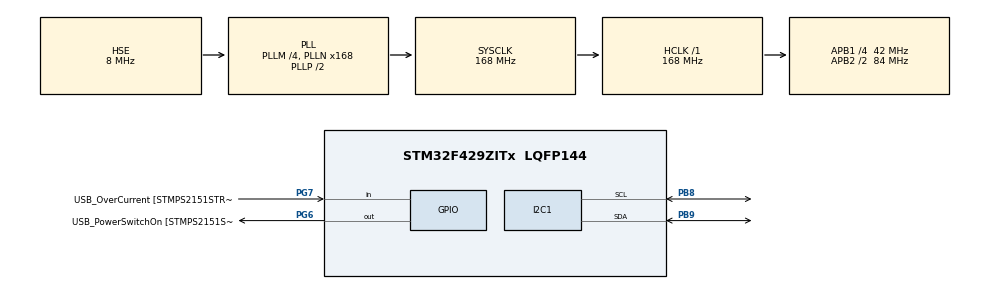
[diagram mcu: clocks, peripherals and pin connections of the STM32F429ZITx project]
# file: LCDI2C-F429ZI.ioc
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Mcu.Family=STM32F4
RCC.PLLSourceVirtual=RCC_PLLSOURCE_HSE
RCC.CortexFreq_Value=168000000
PG6.Signal=GPIO_Output
PG7.Signal=GPIO_Input
PA14.GPIO_Label=TCK
PG6.GPIO_Label=USB_PowerSwitchOn [STMPS2151STR_EN]
RCC.SYSCLKSourceVirtual=RCC_SYSCLKSOURCE_PLLCLK
PC14/OSC32_IN.Mode=LSE-External-Oscillator
RCC.APB1CLKDivider=RCC_HCLK_DIV4
RCC.SYSCLKSource=RCC_SYSCLKSOURCE_PLLCLK
ProjectManager.StackSize=0x400
PA13.Signal=SYS_JTMS-SWDIO
ProjectManager.TargetToolchain=STM32CubeIDE
PH0/OSC_IN.Mode=HSE-External-Clock-Source
RCC.HCLKFreq_Value=168000000
PB9.Mode=I2C
RCC.APB2TimFreq_Value=168000000
PH1/OSC_OUT.Signal=RCC_OSC_OUT
RCC.USBFreq_Value=48000000
RCC.AHBFreq_Value=168000000
RCC.HSE_VALUE=8000000
board=NUCLEO-F429ZI
RCC.VCOOutputFreq_Value=336000000
RCC.PLLMUL=RCC_PLL_MUL9
PH0/OSC_IN.Signal=RCC_OSC_IN
RCC.APB2Freq_Value=84000000
RCC.PRESCALERUSB=RCC_USBCLKSOURCE_PLL_DIV1_5
PA14.Mode=Serial_Wire
PG7.GPIO_Label=USB_OverCurrent [STMPS2151STR_FAULT]
PA13.Mode=Serial_Wire
PH1/OSC_OUT.Mode=HSE-External-Clock-Source
Mcu.Name=STM32F429ZITx
PA13.GPIO_Label=TMS
RCC.APB2TimCLKDivider=2
RCC.48MHZClocksFreq_Value=48000000
RCC.SYSCLKFreq_VALUE=168000000
Mcu.Package=LQFP144
PB9.Signal=I2C1_SDA
PC14/OSC32_IN.Signal=RCC_OSC32_IN
PC15/OSC32_OUT.Mode=LSE-External-Oscillator
PA14.Signal=SYS_JTCK-SWCLK
ProjectManager.HeapSize=0x200
RCC.HSI_VALUE=16000000
PH0/OSC_IN.GPIO_Label=MCO [STM32F103CBT6_PA8]
RCC.PLLQ=7
NVIC.PriorityGroup=NVIC_PRIORITYGROUP_4
RCC.APB2CLKDivider=RCC_HCLK_DIV2
RCC.PLLM=4
PB8.Mode=I2C
RCC.PLLN=168
RCC.APB1TimFreq_Value=84000000
PB8.Signal=I2C1_SCL
PC15/OSC32_OUT.Signal=RCC_OSC32_OUT
RCC.APB1Freq_Value=42000000

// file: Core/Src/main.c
/* USER CODE BEGIN Header */
/**
  ******************************************************************************
  * @file           : main.c
  * @brief          : Main program body
  ******************************************************************************
  * @attention
  *
  * <h2><center>&copy; Copyright (c) 2021 STMicroelectronics.
  * All rights reserved.</center></h2>
  *
  * This software component is licensed by ST under BSD 3-Clause license,
  * the "License"; You may not use this file except in compliance with the
  * License. You may obtain a copy of the License at:
  *                        opensource.org/licenses/BSD-3-Clause
  *
  ******************************************************************************
  */
/* USER CODE END Header */
#include "main.h"

/* USER CODE BEGIN Includes */
#include "LCDI2C.h"
/* USER CODE END Includes */

I2C_HandleTypeDef hi2c1;

void SystemClock_Config(void);
static void MX_GPIO_Init(void);
static void MX_I2C1_Init(void);

int main(void)
{

  /* MCU Configuration--------------------------------------------------------*/

  /* Reset of all peripherals, Initializes the Flash interface and the Systick. */
  HAL_Init();

  /* Configure the system clock */
  SystemClock_Config();

  /* Initialize all configured peripherals */
  MX_GPIO_Init();
  MX_I2C1_Init();
  /* USER CODE BEGIN 2 */
  LCD_initID(0x4E); //I2C Address
  LCD_Init();	//Initialization
  /* USER CODE END 2 */

  /* Infinite loop */
  while (1)
  {
	  LCD_setCursor(0,0);
	  LCD_sendSTR("Hello World");
  }
}

void SystemClock_Config(void)
{
  RCC_OscInitTypeDef RCC_OscInitStruct = {0};
  RCC_ClkInitTypeDef RCC_ClkInitStruct = {0};

  /** Configure the main internal regulator output voltage
  */
  __HAL_RCC_PWR_CLK_ENABLE();
  __HAL_PWR_VOLTAGESCALING_CONFIG(PWR_REGULATOR_VOLTAGE_SCALE1);
  /** Initializes the RCC Oscillators according to the specified parameters
  * in the RCC_OscInitTypeDef structure.
  */
  RCC_OscInitStruct.OscillatorType = RCC_OSCILLATORTYPE_HSE;
  RCC_OscInitStruct.HSEState = RCC_HSE_BYPASS;
  RCC_OscInitStruct.PLL.PLLState = RCC_PLL_ON;
  RCC_OscInitStruct.PLL.PLLSource = RCC_PLLSOURCE_HSE;
  RCC_OscInitStruct.PLL.PLLM = 4;
  RCC_OscInitStruct.PLL.PLLN = 168;
  RCC_OscInitStruct.PLL.PLLP = RCC_PLLP_DIV2;
  RCC_OscInitStruct.PLL.PLLQ = 7;
  if (HAL_RCC_OscConfig(&RCC_OscInitStruct) != HAL_OK)
  {
    Error_Handler();
  }
  /** Initializes the CPU, AHB and APB buses clocks
  */
  RCC_ClkInitStruct.ClockType = RCC_CLOCKTYPE_HCLK|RCC_CLOCKTYPE_SYSCLK
                              |RCC_CLOCKTYPE_PCLK1|RCC_CLOCKTYPE_PCLK2;
  RCC_ClkInitStruct.SYSCLKSource = RCC_SYSCLKSOURCE_PLLCLK;
  RCC_ClkInitStruct.AHBCLKDivider = RCC_SYSCLK_DIV1;
  RCC_ClkInitStruct.APB1CLKDivider = RCC_HCLK_DIV4;
  RCC_ClkInitStruct.APB2CLKDivider = RCC_HCLK_DIV2;

  if (HAL_RCC_ClockConfig(&RCC_ClkInitStruct, FLASH_LATENCY_5) != HAL_OK)
  {
    Error_Handler();
  }
}

static void MX_I2C1_Init(void)
{

  hi2c1.Instance = I2C1;
  hi2c1.Init.ClockSpeed = 100000;
  hi2c1.Init.DutyCycle = I2C_DUTYCYCLE_2;
  hi2c1.Init.OwnAddress1 = 0;
  hi2c1.Init.AddressingMode = I2C_ADDRESSINGMODE_7BIT;
  hi2c1.Init.DualAddressMode = I2C_DUALADDRESS_DISABLE;
  hi2c1.Init.OwnAddress2 = 0;
  hi2c1.Init.GeneralCallMode = I2C_GENERALCALL_DISABLE;
  hi2c1.Init.NoStretchMode = I2C_NOSTRETCH_DISABLE;
  if (HAL_I2C_Init(&hi2c1) != HAL_OK)
  {
    Error_Handler();
  }
  /** Configure Analogue filter
  */
  if (HAL_I2CEx_ConfigAnalogFilter(&hi2c1, I2C_ANALOGFILTER_ENABLE) != HAL_OK)
  {
    Error_Handler();
  }
  /** Configure Digital filter
  */
  if (HAL_I2CEx_ConfigDigitalFilter(&hi2c1, 0) != HAL_OK)
  {
    Error_Handler();
  }

}

static void MX_GPIO_Init(void)
{
  GPIO_InitTypeDef GPIO_InitStruct = {0};

  /* GPIO Ports Clock Enable */
  __HAL_RCC_GPIOC_CLK_ENABLE();
  __HAL_RCC_GPIOH_CLK_ENABLE();
  __HAL_RCC_GPIOG_CLK_ENABLE();
  __HAL_RCC_GPIOA_CLK_ENABLE();
  __HAL_RCC_GPIOB_CLK_ENABLE();

  /*Configure GPIO pin Output Level */
  HAL_GPIO_WritePin(USB_PowerSwitchOn_GPIO_Port, USB_PowerSwitchOn_Pin, GPIO_PIN_RESET);

  /*Configure GPIO pin : USB_PowerSwitchOn_Pin */
  GPIO_InitStruct.Pin = USB_PowerSwitchOn_Pin;
  GPIO_InitStruct.Mode = GPIO_MODE_OUTPUT_PP;
  GPIO_InitStruct.Pull = GPIO_NOPULL;
  GPIO_InitStruct.Speed = GPIO_SPEED_FREQ_LOW;
  HAL_GPIO_Init(USB_PowerSwitchOn_GPIO_Port, &GPIO_InitStruct);

  /*Configure GPIO pin : USB_OverCurrent_Pin */
  GPIO_InitStruct.Pin = USB_OverCurrent_Pin;
  GPIO_InitStruct.Mode = GPIO_MODE_INPUT;
  GPIO_InitStruct.Pull = GPIO_NOPULL;
  HAL_GPIO_Init(USB_OverCurrent_GPIO_Port, &GPIO_InitStruct);

}

void Error_Handler(void)
{
  __disable_irq();
  while (1)
  {
  }
}

/************************ (C) COPYRIGHT STMicroelectronics *****END OF FILE****/
